# MIMXRT685S_cm33 register map
Vendor: nxp.com; File version: 1.0
CPU: CM33 r2p0, little endian, MPU, FPU, VTOR, 3 interrupt priority bits
Registers are 32-bit, read-write, reset 0x0 unless marked. A register's access mark holds for its fields unless they carry their own. Offsets are from the block's base; [hi:lo] are bit positions; {n}, {i} and the like mark numbered series.

## RSTCTL1 — reset ccontroller 1
Base 0x40020000
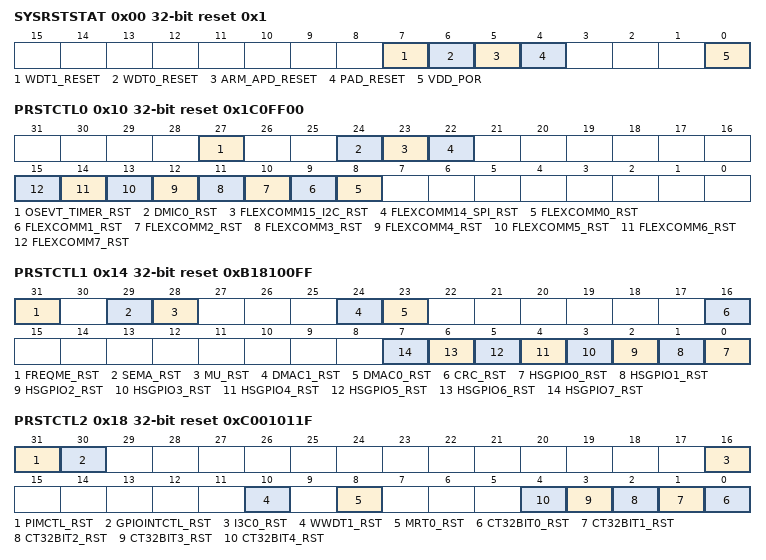
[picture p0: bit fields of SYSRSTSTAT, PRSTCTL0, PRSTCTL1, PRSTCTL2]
0x00 SYSRSTSTAT reset 0x1 — system reset status register
  [7] WDT1_RESET — WDT1 RESET Event Detected:
    0=NO_EVENT_DETECTED; 1=WDT1_RESET_DETECTED (WDT1 reset event detected. (Writing a 1 to this bit clears this status).)
  [6] WDT0_RESET — WDT0 RESET Event Detected:
    0=NO_EVENT_DETECTED; 1=WDT0_RESET_DETECTED (WDT0 reset event detected. (Writing a 1 to this bit clears this status).)
  [5] ARM_APD_RESET — ARM RESET Event Detected:
    0=NO_EVENT_DETECTED; 1=RESET_DETECTED (ARM reset event detected. (Writing a 1 to this bit clears this status).)
  [4] PAD_RESET — PAD RESET Event Detected:
    0=NO_EVENT_DETECTED; 1=RESET_DETECTED (RESET Detected. (Write 1 to CLR),)
  [0] VDD_POR — VDD POR Event Detected:
    0=NO_POR_DETECTED (No event detected.); 1=POR_DETECTED (VDD POR event detected. (Writing a 1 to this bit clears this status).)
0x10 PRSTCTL0 reset 0x1C0FF00 — peripheral reset control register 0
  [all] fields
    0=CLEAR_RESET; 1=SET_RESET
  [27] OSEVT_TIMER_RST — osevent timer reset control
  [24] DMIC0_RST — DMIC0 reset control
  [23] FLEXCOMM15_I2C_RST — FLEXCOMM15 I2C reset control
  [22] FLEXCOMM14_SPI_RST — FLEXCOMM14 SPI reset control
  [n+8] FLEXCOMM{n}_RST (n=0..7) — FLEXCOMM{n} reset control
0x14 PRSTCTL1 reset 0xB18100FF — peripheral reset control register 1
  [all] fields
    0=CLEAR_RESET; 1=SET_RESET
  [31] FREQME_RST — FREQME reset control
  [29] SEMA_RST — SEMA reset control
  [28] MU_RST — MU reset control
  [24] DMAC1_RST — DMAC1 reset control
  [23] DMAC0_RST — DMAC0 reset control
  [16] CRC_RST — CRC reset control
  [n] HSGPIO{n}_RST (n=0..7) — HSGPIO{n} reset control
0x18 PRSTCTL2 reset 0xC001011F — peripheral reset control register 2
  [all] fields
    0=CLEAR_RESET; 1=SET_RESET
  [31] PIMCTL_RST — PMC reset control
  [30] GPIOINTCTL_RST — GPIOINTCTL reset control
  [16] I3C0_RST — I3C0 reset control
  [10] WWDT1_RST — WWDT1 reset control
  [8] MRT0_RST — MRT0 reset control
  [n] CT32BIT{n}_RST (n=0..4) — CT32BIT{n} reset control
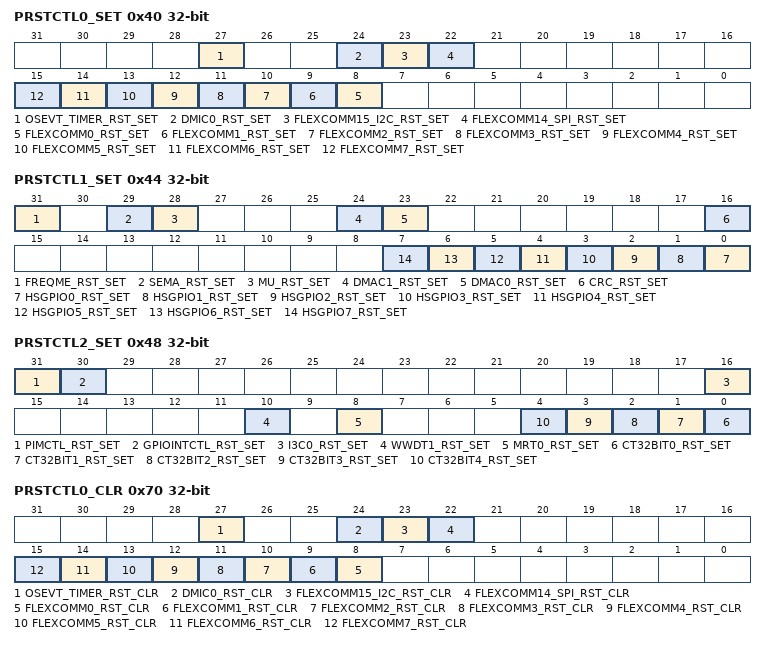
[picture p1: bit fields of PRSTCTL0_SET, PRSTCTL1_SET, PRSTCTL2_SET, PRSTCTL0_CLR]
0x40 PRSTCTL0_SET wo reset not defined — peripheral reset set register 0
  [all] fields
    0=NO_EFFECT; 1=SET_RESET (Sets the PRSTCTL0 Bit)
  [27] OSEVT_TIMER_RST_SET — osevent timer reset set
  [24] DMIC0_RST_SET — DMIC0 reset set
  [23] FLEXCOMM15_I2C_RST_SET — FLEXCOMM15 I2C reset set
  [22] FLEXCOMM14_SPI_RST_SET — FLEXCOMM14 SPI reset set
  [n+8] FLEXCOMM{n}_RST_SET (n=0..7) — FLEXCOMM{n} reset set
0x44 PRSTCTL1_SET wo reset not defined — peripheral reset set register 1
  [all] fields
    0=NO_EFFECT; 1=SET_RESET (Sets the PRSTCTL1 Bit)
  [31] FREQME_RST_SET — FREQME reset set
  [29] SEMA_RST_SET — SEMA reset set
  [28] MU_RST_SET — MU reset set
  [24] DMAC1_RST_SET — DMAC1 reset set
  [23] DMAC0_RST_SET — DMAC0 reset set
  [16] CRC_RST_SET — CRC reset set
  [n] HSGPIO{n}_RST_SET (n=0..7) — HSGPIO{n} reset set
0x48 PRSTCTL2_SET wo reset not defined — peripheral reset set register 2
  [all] fields
    0=NO_EFFECT; 1=SET_RESET (Sets the PRSTCTL2 Bit)
  [31] PIMCTL_RST_SET — PMC reset set
  [30] GPIOINTCTL_RST_SET — GPIOINTCTL reset set
  [16] I3C0_RST_SET — I3C0 reset set
  [10] WWDT1_RST_SET — WWDT1 reset set
  [8] MRT0_RST_SET — MRT0 reset set
  [n] CT32BIT{n}_RST_SET (n=0..4) — CT32BIT{n} reset set
0x70 PRSTCTL0_CLR wo reset not defined — peripheral reset clear register 0
  [all] fields
    0=NO_EFFECT; 1=CLR_RESET (clears the PRSTCTL0 Bit)
  [27] OSEVT_TIMER_RST_CLR — osevent timer reset clear
  [24] DMIC0_RST_CLR — DMIC0 reset clear
  [23] FLEXCOMM15_I2C_RST_CLR — FLEXCOMM15 I2C reset clear
  [22] FLEXCOMM14_SPI_RST_CLR — FLEXCOMM14 SPI reset clear
  [n+8] FLEXCOMM{n}_RST_CLR (n=0..7) — FLEXCOMM{n} reset clear
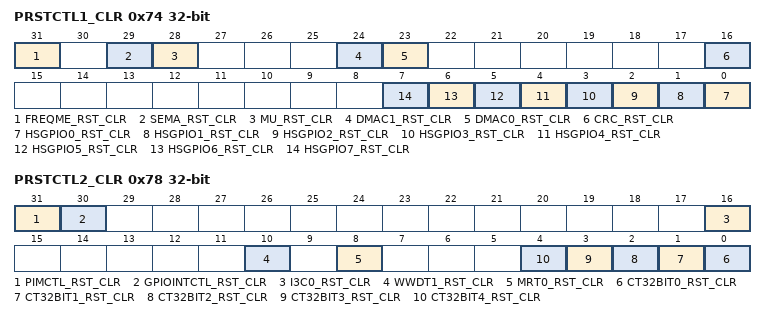
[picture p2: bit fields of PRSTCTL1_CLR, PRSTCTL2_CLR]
0x74 PRSTCTL1_CLR wo reset not defined — peripheral reset clear register 1
  [all] fields
    0=NO_EFFECT; 1=CLR_RESET (clears the PRSTCTL1 Bit)
  [31] FREQME_RST_CLR — FREQME reset clear
  [29] SEMA_RST_CLR — SEMA reset clear
  [28] MU_RST_CLR — MU reset clear
  [24] DMAC1_RST_CLR — DMAC1 reset clear
  [23] DMAC0_RST_CLR — DMAC0 reset clear
  [16] CRC_RST_CLR — CRC reset clear
  [n] HSGPIO{n}_RST_CLR (n=0..7) — HSGPIO{n} reset clear
0x78 PRSTCTL2_CLR wo reset not defined — peripheral reset clear register 2
  [31] PIMCTL_RST_CLR — PMC reset clear
    0=NO_EFFECT; 1=CLR_RESET (clears the PRSTCTL2 Bit)
  [30] GPIOINTCTL_RST_CLR — GPIOINTCTL reset clear
    0=NO_EFFECT; 1=CLR_RESET (clears the PRSTCTL2 Bit)
  [16] I3C0_RST_CLR — I3C0 reset clear
    1=SET_RESET (Sets the PRSTCTL2 Bit)
  [10] WWDT1_RST_CLR — WWDT1 reset clear
    0=NO_EFFECT; 1=CLR_RESET (clears the PRSTCTL2 Bit)
  [8] MRT0_RST_CLR — MRT0 reset clear
    0=NO_EFFECT; 1=CLR_RESET (clears the PRSTCTL2 Bit)
  [n] CT32BIT{n}_RST_CLR (n=0..4) — CT32BIT{n} reset clear
    0=NO_EFFECT; 1=CLR_RESET (clears the PRSTCTL2 Bit)
